# Air001xx_DFP register map
Vendor: AirM2M; Series: Air001; File version: 1.0.0
CPU: CM0+ r0p1, little endian, no MPU, no FPU, 4 interrupt priority bits
Registers are 32-bit, read-write, reset 0x0 unless marked. A register's access mark holds for its fields unless they carry their own. Offsets are from the block's base; [hi:lo] are bit positions.

## USART1 — Universal synchronous asynchronous receiver transmitter
Base 0x40013800
Same registers: USART2 0x40004400
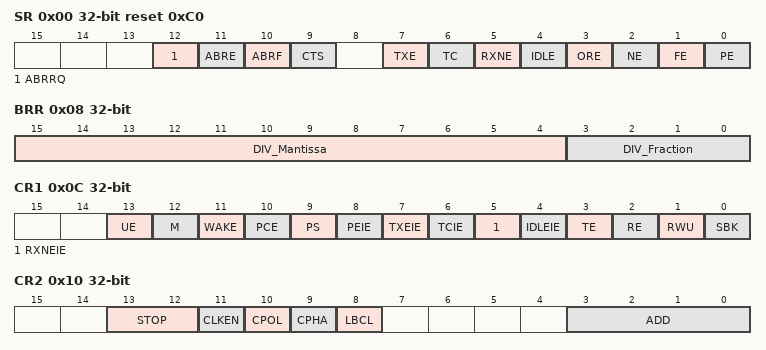
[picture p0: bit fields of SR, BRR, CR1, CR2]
0x00 SR reset 0xC0 — Status register
  [12] ABRRQ wo — Automate baudrate detection requeset
  [11] ABRE ro — Automate baudrate detection error flag
  [10] ABRF ro — Automate baudrate detection flag
  [9] CTS — CTS flag
  [7] TXE ro — Transmit data register empty
  [6] TC — Transmission complete
  [5] RXNE — Read data register not empty
  [4] IDLE ro — IDLE line detected
  [3] ORE ro — Overrun error
  [2] NE ro — Noise error flag
  [1] FE ro — Framing error
  [0] PE ro — Parity error
0x04 DR — Data register
  [8:0] DR — Data value
0x08 BRR — Baud rate register
  [15:4] DIV_Mantissa — mantissa of USARTDIV
  [3:0] DIV_Fraction — fraction of USARTDIV
0x0C CR1 — Control register 1
  [13] UE — USART enable
  [12] M — Word length
  [11] WAKE — Wakeup method
  [10] PCE — Parity control enable
  [9] PS — Parity selection
  [8] PEIE — PE interrupt enable
  [7] TXEIE — TXE interrupt enable
  [6] TCIE — Transmission complete interrupt enable
  [5] RXNEIE — RXNE interrupt enable
  [4] IDLEIE — IDLE interrupt enable
  [3] TE — Transmitter enable
  [2] RE — Receiver enable
  [1] RWU — Receiver wakeup
  [0] SBK — Send break
0x10 CR2 — Control register 2
  [13:12] STOP — STOP bits
  [11] CLKEN — Clock enable
  [10] CPOL — Clock polarity
  [9] CPHA — Clock phase
  [8] LBCL — Last bit clock pulse
  [3:0] ADD — Address of the USART node
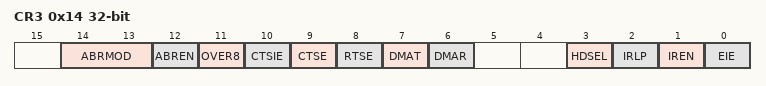
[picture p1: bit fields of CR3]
0x14 CR3 — Control register 3
  [14:13] ABRMOD — Auto baudrate mode
  [12] ABREN — Auto baudrate enable
  [11] OVER8 — Oversampling mode
  [10] CTSIE — CTS interrupt enable
  [9] CTSE — CTS enable
  [8] RTSE — RTS enable
  [7] DMAT — DMA enable transmitter
  [6] DMAR — DMA enable receiver
  [3] HDSEL — Half-duplex selection
  [2] IRLP — IrDA low-power
  [1] IREN — IrDA mode enable
  [0] EIE — Error interrupt enable

## RTC — Real time clock
Base 0x40002800
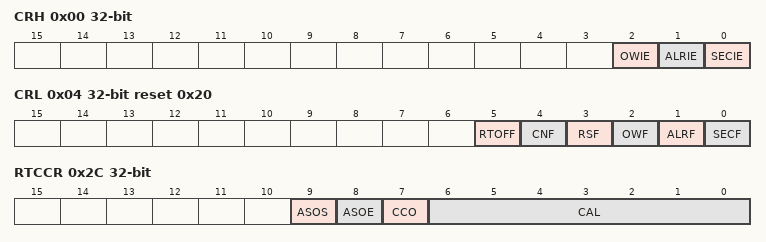
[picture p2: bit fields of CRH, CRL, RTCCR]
0x00 CRH — RTC Control Register High
  [2] OWIE — Overflow interrupt Enable
  [1] ALRIE — Alarm interrupt Enable
  [0] SECIE — Second interrupt Enable
0x04 CRL reset 0x20 — RTC Control Register Low
  [5] RTOFF ro — RTC operation OFF
  [4] CNF — Configuration Flag
  [3] RSF — Registers Synchronized Flag
  [2] OWF — Overflow Flag
  [1] ALRF — Alarm Flag
  [0] SECF — Second Flag
0x08 PRLH wo — RTC Prescaler Load Register High
  [3:0] PRLH
0x0C PRLL wo reset 0x8000 — RTC Prescaler Load Register Low
  [15:0] PRLL — RTC Prescaler Divider Register Low
0x10 DIVH ro — RTC Prescaler Divider Register High
  [3:0] DIVH — RTC prescaler divider register high
0x14 DIVL ro reset 0x8000 — RTC Prescaler Divider Register Low
  [15:0] DIVL — RTC prescaler divider register Low
0x18 CNTH — RTC Counter Register High
  [15:0] CNTH — RTC counter register high
0x1C CNTL — RTC Counter Register Low
  [15:0] CNTL — RTC counter register Low
0x20 ALRH wo reset 0xFFFF — RTC Alarm Register High
  [15:0] ALRH — RTC alarm register high
0x24 ALRL wo reset 0xFFFF — RTC Alarm Register Low
  [15:0] ALRL — RTC alarm register low
0x2C RTCCR — RTC clock calibration
  [9] ASOS — Alarm or second output selection
  [8] ASOE — Alarm or second output enable
  [7] CCO — Calibration clock output
  [6:0] CAL — Calibration value

## IWDG — Independent watchdog
Base 0x40003000
0x00 KR wo — Key register (IWDG_KR)
  [15:0] KEY — Key value
0x04 PR — Prescaler register (IWDG_PR)
  [2:0] PR — Prescaler divider
0x08 RLR reset 0xFFF — Reload register (IWDG_RLR)
  [11:0] RL — Watchdog counter reload value
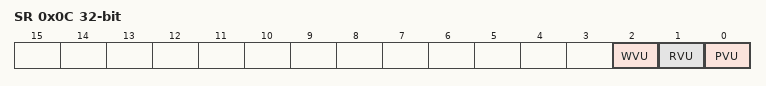
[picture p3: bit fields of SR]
0x0C SR ro — Status register (IWDG_SR)
  [2] WVU — Watchdog counter window value update
  [1] RVU — Watchdog counter reload value update
  [0] PVU — Watchdog prescaler value update
0x10 WINR ro — Window register (IWDG_SR)
  [11:0] WIN — window counter
